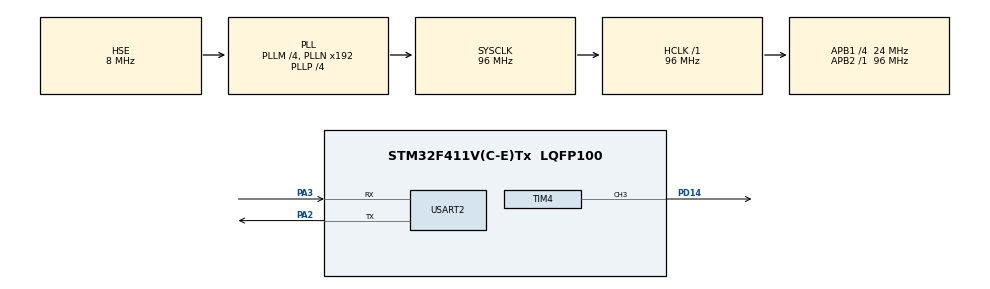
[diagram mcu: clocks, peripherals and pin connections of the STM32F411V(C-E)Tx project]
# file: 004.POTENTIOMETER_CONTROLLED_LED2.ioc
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Mcu.Family=STM32F4
Mcu.Name=STM32F411V(C-E)Tx
Mcu.Package=LQFP100
NVIC.PriorityGroup=NVIC_PRIORITYGROUP_0
NVIC.USART2_IRQn=true\:0\:0\:false\:false\:true\:true\:true\:true
PA13.Mode=Serial_Wire
PA13.Signal=SYS_JTMS-SWDIO
PA14.Mode=Serial_Wire
PA14.Signal=SYS_JTCK-SWCLK
PA2.Mode=Asynchronous
PA2.Signal=USART2_TX
PA3.Mode=Asynchronous
PA3.Signal=USART2_RX
PC14-OSC32_IN.Mode=LSE-External-Oscillator
PC14-OSC32_IN.Signal=RCC_OSC32_IN
PC15-OSC32_OUT.Mode=LSE-External-Oscillator
PC15-OSC32_OUT.Signal=RCC_OSC32_OUT
PD14.Signal=S_TIM4_CH3
PH0\ -\ OSC_IN.Mode=HSE-External-Oscillator
PH0\ -\ OSC_IN.Signal=RCC_OSC_IN
PH1\ -\ OSC_OUT.Mode=HSE-External-Oscillator
PH1\ -\ OSC_OUT.Signal=RCC_OSC_OUT
ProjectManager.HeapSize=0x200
ProjectManager.StackSize=0x400
ProjectManager.TargetToolchain=STM32CubeIDE
RCC.48MHZClocksFreq_Value=48000000
RCC.AHBFreq_Value=96000000
RCC.APB1CLKDivider=RCC_HCLK_DIV4
RCC.APB1Freq_Value=24000000
RCC.APB1TimFreq_Value=48000000
RCC.APB2Freq_Value=96000000
RCC.APB2TimFreq_Value=96000000
RCC.CortexFreq_Value=96000000
RCC.HCLKFreq_Value=96000000
RCC.HSE_VALUE=8000000
RCC.HSI_VALUE=16000000
RCC.PLLI2SM=5
RCC.PLLI2SN=200
RCC.PLLM=4
RCC.PLLP=RCC_PLLP_DIV4
RCC.PLLQ=8
RCC.PLLSourceVirtual=RCC_PLLSOURCE_HSE
RCC.SYSCLKFreq_VALUE=96000000
RCC.SYSCLKSource=RCC_SYSCLKSOURCE_PLLCLK
RCC.VCOOutputFreq_Value=384000000
SH.S_TIM4_CH3.0=TIM4_CH3,PWM Generation3 CH3
TIM4.Channel-PWM\ Generation3\ CH3=TIM_CHANNEL_3
TIM4.Period=999
TIM4.Prescaler=83
USART2.VirtualMode=VM_ASYNC
board=STM32F411E-DISCO

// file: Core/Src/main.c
/* USER CODE BEGIN Header */
/**
  ******************************************************************************
  * @file           : main.c
  * @brief          : Main program body
  ******************************************************************************
  * @attention
  *
  * Copyright (c) 2025 STMicroelectronics.
  * All rights reserved.
  *
  * This software is licensed under terms that can be found in the LICENSE file
  * in the root directory of this software component.
  * If no LICENSE file comes with this software, it is provided AS-IS.
  *
  ******************************************************************************
  */
/* USER CODE END Header */
#include "main.h"
#include "string.h"
#include "stdio.h"
#include <stdlib.h>

TIM_HandleTypeDef htim4;

UART_HandleTypeDef huart2;

/* USER CODE BEGIN PV */
char rxBuffer[10];
uint8_t rxIndex = 0;
uint32_t pwmVal = 0;
/* USER CODE END PV */

void SystemClock_Config(void);
static void MX_GPIO_Init(void);
static void MX_TIM4_Init(void);
static void MX_USART2_UART_Init(void);

int main(void)
{

  /* MCU Configuration--------------------------------------------------------*/

  /* Reset of all peripherals, Initializes the Flash interface and the Systick. */
  HAL_Init();

  /* Configure the system clock */
  SystemClock_Config();

  /* Initialize all configured peripherals */
  MX_GPIO_Init();
  MX_TIM4_Init();
  MX_USART2_UART_Init();
  /* USER CODE BEGIN 2 */
  HAL_TIM_PWM_Start(&htim4, TIM_CHANNEL_3); // PWM başlat
      HAL_UART_Receive_IT(&huart2, (uint8_t *)&rxBuffer[rxIndex], 1); // UART başlat

  /* USER CODE END 2 */

  /* Infinite loop */
  while (1)
  {

  }
}

void SystemClock_Config(void)
{
  RCC_OscInitTypeDef RCC_OscInitStruct = {0};
  RCC_ClkInitTypeDef RCC_ClkInitStruct = {0};

  /** Configure the main internal regulator output voltage
  */
  __HAL_RCC_PWR_CLK_ENABLE();
  __HAL_PWR_VOLTAGESCALING_CONFIG(PWR_REGULATOR_VOLTAGE_SCALE1);

  /** Initializes the RCC Oscillators according to the specified parameters
  * in the RCC_OscInitTypeDef structure.
  */
  RCC_OscInitStruct.OscillatorType = RCC_OSCILLATORTYPE_HSE;
  RCC_OscInitStruct.HSEState = RCC_HSE_ON;
  RCC_OscInitStruct.PLL.PLLState = RCC_PLL_ON;
  RCC_OscInitStruct.PLL.PLLSource = RCC_PLLSOURCE_HSE;
  RCC_OscInitStruct.PLL.PLLM = 4;
  RCC_OscInitStruct.PLL.PLLN = 192;
  RCC_OscInitStruct.PLL.PLLP = RCC_PLLP_DIV4;
  RCC_OscInitStruct.PLL.PLLQ = 8;
  if (HAL_RCC_OscConfig(&RCC_OscInitStruct) != HAL_OK)
  {
    Error_Handler();
  }

  /** Initializes the CPU, AHB and APB buses clocks
  */
  RCC_ClkInitStruct.ClockType = RCC_CLOCKTYPE_HCLK|RCC_CLOCKTYPE_SYSCLK
                              |RCC_CLOCKTYPE_PCLK1|RCC_CLOCKTYPE_PCLK2;
  RCC_ClkInitStruct.SYSCLKSource = RCC_SYSCLKSOURCE_PLLCLK;
  RCC_ClkInitStruct.AHBCLKDivider = RCC_SYSCLK_DIV1;
  RCC_ClkInitStruct.APB1CLKDivider = RCC_HCLK_DIV4;
  RCC_ClkInitStruct.APB2CLKDivider = RCC_HCLK_DIV1;

  if (HAL_RCC_ClockConfig(&RCC_ClkInitStruct, FLASH_LATENCY_3) != HAL_OK)
  {
    Error_Handler();
  }
}

static void MX_TIM4_Init(void)
{

  TIM_MasterConfigTypeDef sMasterConfig = {0};
  TIM_OC_InitTypeDef sConfigOC = {0};

  htim4.Instance = TIM4;
  htim4.Init.Prescaler = 83;
  htim4.Init.CounterMode = TIM_COUNTERMODE_UP;
  htim4.Init.Period = 999;
  htim4.Init.ClockDivision = TIM_CLOCKDIVISION_DIV1;
  htim4.Init.AutoReloadPreload = TIM_AUTORELOAD_PRELOAD_DISABLE;
  if (HAL_TIM_PWM_Init(&htim4) != HAL_OK)
  {
    Error_Handler();
  }
  sMasterConfig.MasterOutputTrigger = TIM_TRGO_RESET;
  sMasterConfig.MasterSlaveMode = TIM_MASTERSLAVEMODE_DISABLE;
  if (HAL_TIMEx_MasterConfigSynchronization(&htim4, &sMasterConfig) != HAL_OK)
  {
    Error_Handler();
  }
  sConfigOC.OCMode = TIM_OCMODE_PWM1;
  sConfigOC.Pulse = 0;
  sConfigOC.OCPolarity = TIM_OCPOLARITY_HIGH;
  sConfigOC.OCFastMode = TIM_OCFAST_DISABLE;
  if (HAL_TIM_PWM_ConfigChannel(&htim4, &sConfigOC, TIM_CHANNEL_3) != HAL_OK)
  {
    Error_Handler();
  }
  HAL_TIM_MspPostInit(&htim4);

}

static void MX_USART2_UART_Init(void)
{

  huart2.Instance = USART2;
  huart2.Init.BaudRate = 115200;
  huart2.Init.WordLength = UART_WORDLENGTH_8B;
  huart2.Init.StopBits = UART_STOPBITS_1;
  huart2.Init.Parity = UART_PARITY_NONE;
  huart2.Init.Mode = UART_MODE_TX_RX;
  huart2.Init.HwFlowCtl = UART_HWCONTROL_NONE;
  huart2.Init.OverSampling = UART_OVERSAMPLING_16;
  if (HAL_UART_Init(&huart2) != HAL_OK)
  {
    Error_Handler();
  }

}

static void MX_GPIO_Init(void)
{

  /* GPIO Ports Clock Enable */
  __HAL_RCC_GPIOC_CLK_ENABLE();
  __HAL_RCC_GPIOH_CLK_ENABLE();
  __HAL_RCC_GPIOA_CLK_ENABLE();
  __HAL_RCC_GPIOD_CLK_ENABLE();

}

/* USER CODE BEGIN 4 */
void HAL_UART_RxCpltCallback(UART_HandleTypeDef *huart)
{
    if (huart->Instance == USART2)
    {
        char received = rxBuffer[rxIndex];

        if (received == '\n' || received == '\r')
        {
            rxBuffer[rxIndex] = '\0';
            pwmVal = atoi(rxBuffer);

            if (pwmVal > 999) pwmVal = 999; // Max PWM
            __HAL_TIM_SET_COMPARE(&htim4, TIM_CHANNEL_3, pwmVal);

            // PWM değerini geri gönder
            char msg[30];
            sprintf(msg, "PWM set: %lu\r\n", pwmVal);
            HAL_UART_Transmit(&huart2, (uint8_t *)msg, strlen(msg), HAL_MAX_DELAY);

            rxIndex = 0; // Reset buffer
        }
        else
        {
            rxIndex++;
            if (rxIndex >= sizeof(rxBuffer)) rxIndex = 0;
        }

        HAL_UART_Receive_IT(&huart2, (uint8_t *)&rxBuffer[rxIndex], 1);
    }
}

/* USER CODE END 4 */

void Error_Handler(void)
{
  __disable_irq();
  while (1)
  {
  }
}
